# CH32F20xxx register map
Vendor: WCH Ltd.; File version: 1.1
Registers are 32-bit, read-write, reset 0x0 unless marked. A register's access mark holds for its fields unless they carry their own. Offsets are from the block's base; [hi:lo] are bit positions; {n}, {i} and the like mark numbered series; 'fields as' and 'values as' point back to an identical list.

## CAN1 — Controller area network
Base 0x40006400
Same registers: CAN2 0x40006800
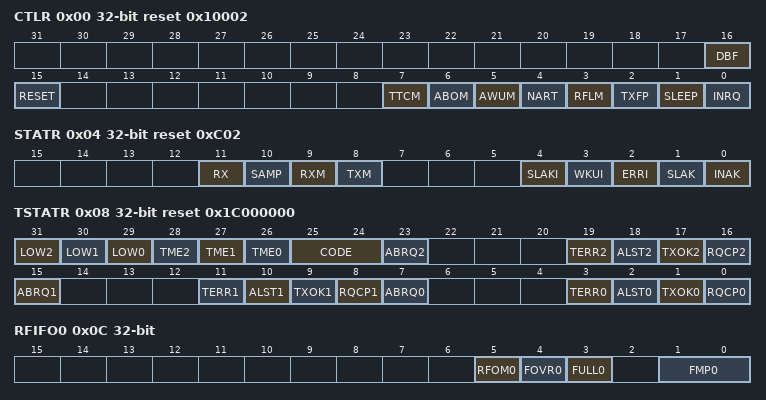
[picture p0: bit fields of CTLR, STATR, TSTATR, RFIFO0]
0x00 CTLR reset 0x10002 — CAN Master control register
  [16] DBF — Debug freeze
  [15] RESET — Software master reset
  [7] TTCM — Time triggered communication mode
  [6] ABOM — Automatic bus-off management
  [5] AWUM — Automatic wakeup mode
  [4] NART — No automatic retransmission
  [3] RFLM — Receive FIFO locked mode
  [2] TXFP — Transmit FIFO priority
  [1] SLEEP — Sleep mode request
  [0] INRQ — Initialization request
0x04 STATR access per field reset 0xC02 — CAN master status register
  [11] RX ro — Rx signal
  [10] SAMP ro — Last sample point
  [9] RXM ro — Receive mode
  [8] TXM ro — Transmit mode
  [4] SLAKI rw — Sleep acknowledge interrupt
  [3] WKUI rw — Wakeup interrupt
  [2] ERRI rw — Error interrupt
  [1] SLAK ro — Sleep acknowledge
  [0] INAK ro — Initialization acknowledge
0x08 TSTATR access per field reset 0x1C000000 — CAN transmit status register
  [31] LOW2 ro — Lowest priority flag for mailbox 2
  [30] LOW1 ro — Lowest priority flag for mailbox 1
  [29] LOW0 ro — Lowest priority flag for mailbox 0
  [28] TME2 ro — Transmit mailbox 2 empty
  [27] TME1 ro — Transmit mailbox 1 empty
  [26] TME0 ro — Transmit mailbox 0 empty
  [25:24] CODE ro — Mailbox code
  [23] ABRQ2 rw — Abort request for mailbox 2
  [19] TERR2 rw — Transmission error of mailbox 2
  [18] ALST2 rw — Arbitration lost for mailbox 2
  [17] TXOK2 rw — Transmission OK of mailbox 2
  [16] RQCP2 rw — Request completed mailbox2
  [15] ABRQ1 rw — Abort request for mailbox 1
  [11] TERR1 rw — Transmission error of mailbox1
  [10] ALST1 rw — Arbitration lost for mailbox1
  [9] TXOK1 rw — Transmission OK of mailbox1
  [8] RQCP1 rw — Request completed mailbox1
  [7] ABRQ0 rw — Abort request for mailbox0
  [3] TERR0 rw — Transmission error of mailbox0
  [2] ALST0 rw — Arbitration lost for mailbox0
  [1] TXOK0 rw — Transmission OK of mailbox0
  [0] RQCP0 rw — Request completed mailbox0
0x0C RFIFO0 access per field — CAN receive FIFO 0 register
  [5] RFOM0 rw — Release FIFO 0 output mailbox
  [4] FOVR0 rw — FIFO 0 overrun
  [3] FULL0 rw — FIFO 0 full
  [1:0] FMP0 ro — FIFO 0 message pending
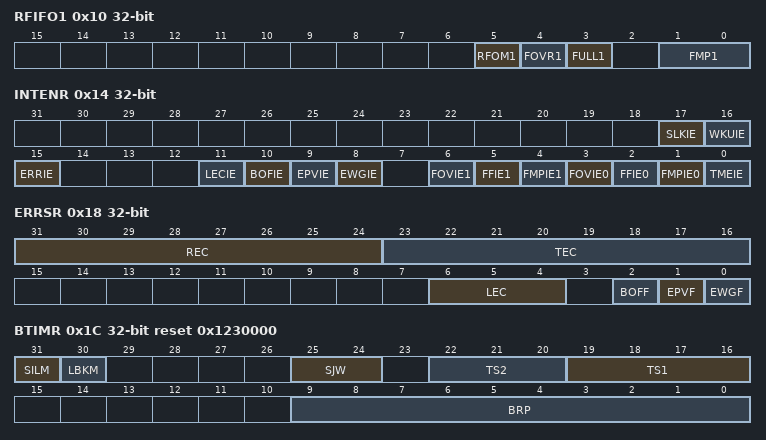
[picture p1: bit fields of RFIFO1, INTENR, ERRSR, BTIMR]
0x10 RFIFO1 access per field — CAN receive FIFO 1 register
  [5] RFOM1 rw — Release FIFO 1 output mailbox
  [4] FOVR1 rw — FIFO 1 overrun
  [3] FULL1 rw — FIFO 1 full
  [1:0] FMP1 ro — FIFO 1 message pending
0x14 INTENR — CAN interrupt enable register
  [17] SLKIE — Sleep interrupt enable
  [16] WKUIE — Wakeup interrupt enable
  [15] ERRIE — Error interrupt enable
  [11] LECIE — Last error code interrupt enable
  [10] BOFIE — Bus-off interrupt enable
  [9] EPVIE — Error passive interrupt enable
  [8] EWGIE — Error warning interrupt enable
  [6] FOVIE1 — FIFO overrun interrupt enable
  [5] FFIE1 — FIFO full interrupt enable
  [4] FMPIE1 — FIFO message pending interrupt enable
  [3] FOVIE0 — FIFO overrun interrupt enable
  [2] FFIE0 — FIFO full interrupt enable
  [1] FMPIE0 — FIFO message pending interrupt enable
  [0] TMEIE — Transmit mailbox empty interrupt enable
0x18 ERRSR access per field — CAN error status register
  [31:24] REC ro — Receive error counter
  [23:16] TEC ro — Least significant byte of the 9-bit transmit error counter
  [6:4] LEC rw — Last error code
  [2] BOFF ro — Bus-off flag
  [1] EPVF ro — Error passive flag
  [0] EWGF ro — Error warning flag
0x1C BTIMR reset 0x1230000 — CAN bit timing register
  [31] SILM — Silent mode (debug)
  [30] LBKM — Loop back mode (debug)
  [25:24] SJW — Resynchronization jump width
  [22:20] TS2 — Time segment 2
  [19:16] TS1 — Time segment 1
  [9:0] BRP — Baud rate prescaler
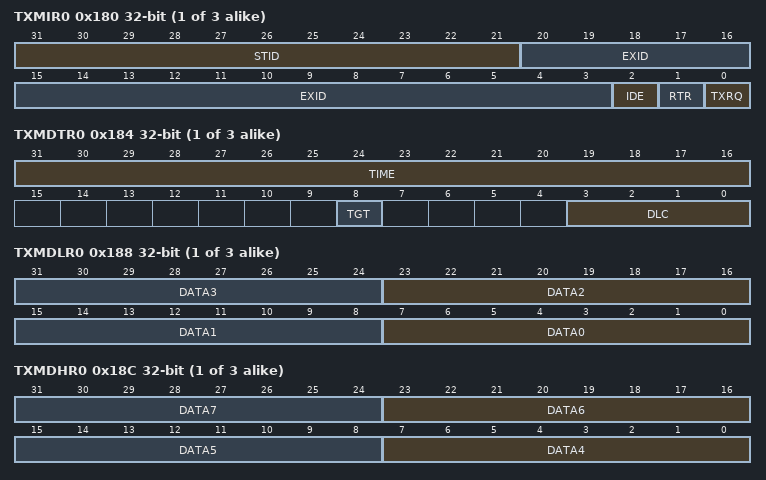
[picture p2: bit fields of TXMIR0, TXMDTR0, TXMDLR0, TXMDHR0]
{0x180+0x10*i} TXMIR{i} (i=0..2) — CAN TX mailbox identifier register
  [31:21] STID — Standard identifier
  [20:3] EXID — extended identifier
  [2] IDE — Identifier extension
  [1] RTR — Remote transmission request
  [0] TXRQ — Transmit mailbox request
{0x184+0x10*i} TXMDTR{i} (i=0..2) — CAN mailbox data length control and time stamp register
  [31:16] TIME — Message time stamp
  [8] TGT — Transmit global time
  [3:0] DLC — Data length code
{0x188+0x10*i} TXMDLR{i} (i=0..2) — CAN mailbox data low register
  [8n+7:8n] DATA{n} (n=0..3) — Data byte {n}
{0x18C+0x10*i} TXMDHR{i} (i=0..2) — CAN mailbox data high register
  [8n-25:8n-32] DATA{n} (n=4..7) — Data byte {n}
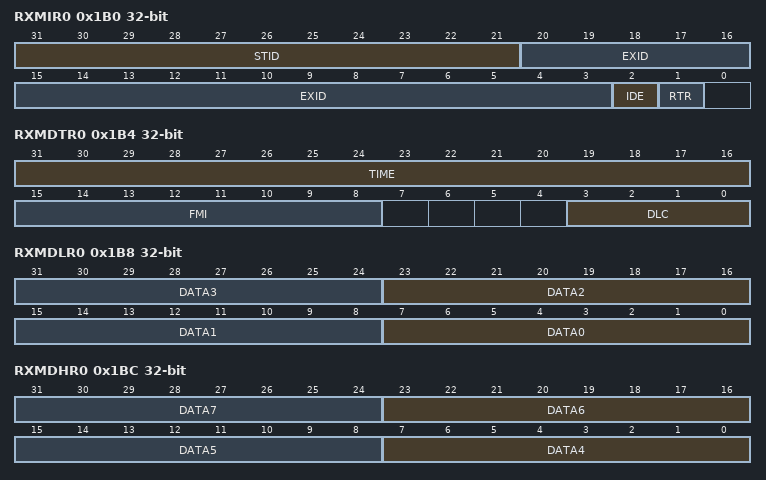
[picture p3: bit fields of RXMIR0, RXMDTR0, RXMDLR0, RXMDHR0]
0x1B0 RXMIR0 ro — CAN receive FIFO mailbox identifier register
  [31:21] STID — Standard identifier
  [20:3] EXID — extended identifier
  [2] IDE — Identifier extension
  [1] RTR — Remote transmission request
0x1B4 RXMDTR0 ro — CAN receive FIFO mailbox data length control and time stamp register
  [31:16] TIME — Message time stamp
  [15:8] FMI — Filter match index
  [3:0] DLC — Data length code
0x1B8 RXMDLR0 ro — CAN receive FIFO mailbox data low register
  [8n+7:8n] DATA{n} (n=0..3) — Data Byte {n}
0x1BC RXMDHR0 ro — CAN receive FIFO mailbox data high register
  [8n-25:8n-32] DATA{n} (n=4..7)
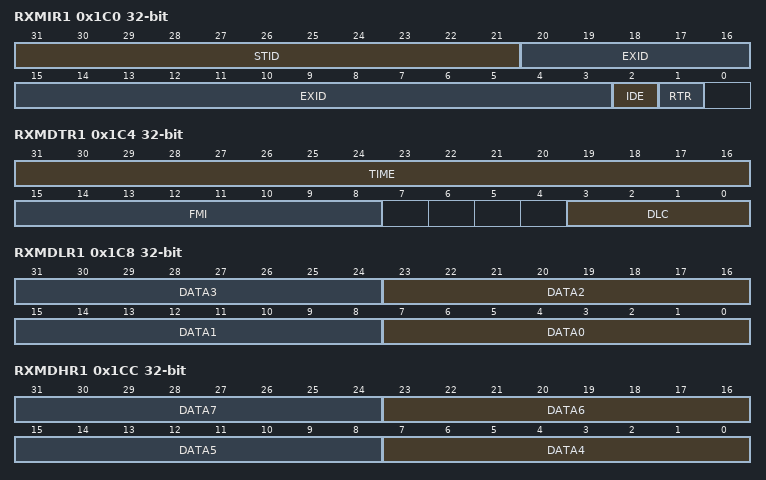
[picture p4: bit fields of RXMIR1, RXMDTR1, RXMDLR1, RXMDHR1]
0x1C0 RXMIR1 ro — CAN receive FIFO mailbox identifier register
  fields as RXMIR0
0x1C4 RXMDTR1 ro — CAN receive FIFO mailbox data length control and time stamp register
  fields as RXMDTR0
0x1C8 RXMDLR1 ro — CAN receive FIFO mailbox data low register
  [8n+7:8n] DATA{n} (n=0..3) — Data Byte {n}
0x1CC RXMDHR1 ro — CAN receive FIFO mailbox data high register
  [8n-25:8n-32] DATA{n} (n=4..7)
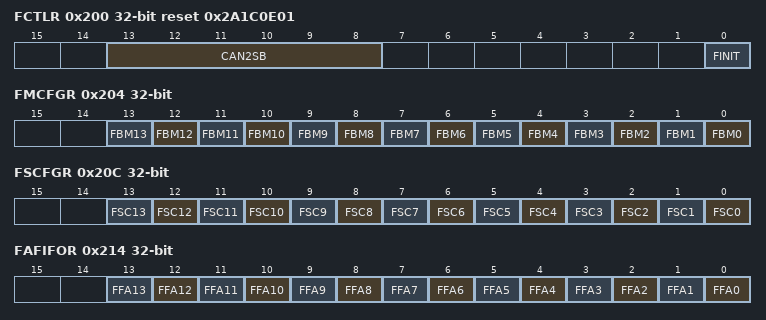
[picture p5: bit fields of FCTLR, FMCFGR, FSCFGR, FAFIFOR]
0x200 FCTLR reset 0x2A1C0E01 — CAN filter master register
  [13:8] CAN2SB — CAN2 start bank
  [0] FINIT — Filter init mode
0x204 FMCFGR — CAN filter mode register
  [n] FBM{n} (n=0..13) — Filter mode
0x20C FSCFGR — CAN filter scale register
  [n] FSC{n} (n=0..13) — Filter scale configuration
0x214 FAFIFOR — CAN filter FIFO assignment register
  [n] FFA{n} (n=0..13) — Filter FIFO assignment for filter {n}
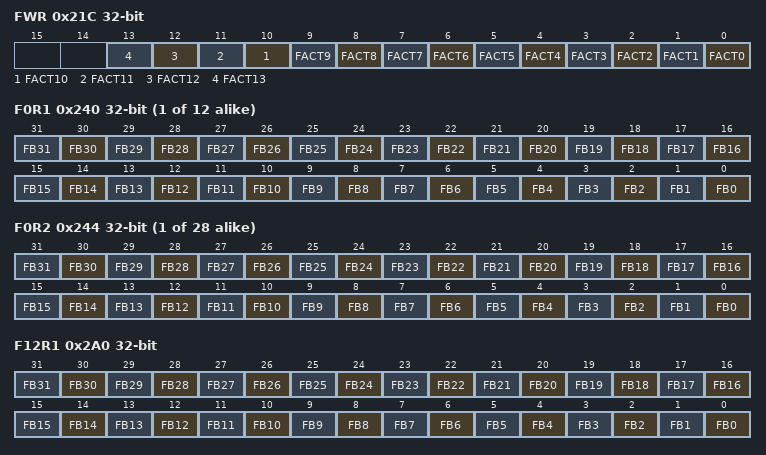
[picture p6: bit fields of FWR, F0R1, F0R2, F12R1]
0x21C FWR — CAN filter activation register
  [n] FACT{n} (n=0..13) — Filter active
{0x240+8i} F{i}R1 (i=0..11) — Filter bank {i} register 1
  [n] FB{n} (n=0..31) — Filter bits
{0x244+8i} F{i}R2 (i=0..27) — Filter bank {i} register 2
  [n] FB{n} (n=0..31) — Filter bits
0x2A0 F12R1 — Filter bank 4 register 1
  [n] FB{n} (n=0..31) — Filter bits
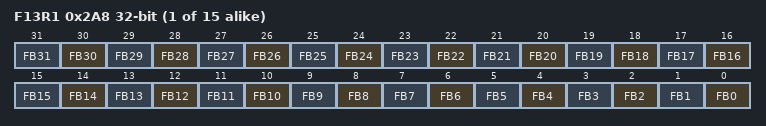
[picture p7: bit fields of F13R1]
{0x240+8i} F{i}R1 (i=13..27) — Filter bank {i} register 1
  [n] FB{n} (n=0..31) — Filter bits
